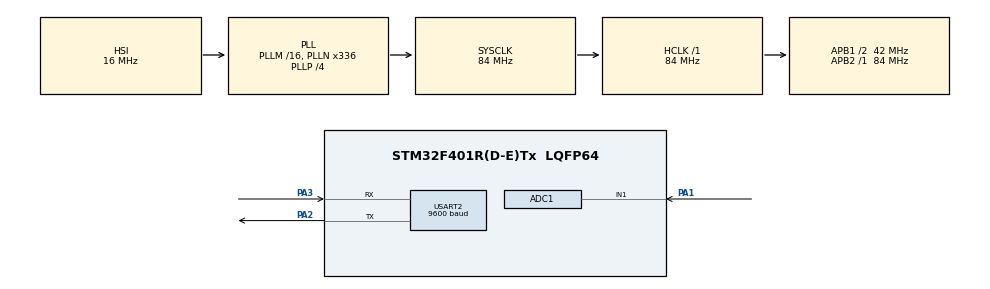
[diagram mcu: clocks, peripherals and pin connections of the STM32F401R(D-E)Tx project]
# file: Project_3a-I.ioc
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ADC1.Channel-0\#ChannelRegularConversion=ADC_CHANNEL_1
ADC1.NbrOfConversion=1
ADC1.NbrOfConversionFlag=1
ADC1.Rank-0\#ChannelRegularConversion=1
ADC1.SamplingTime-0\#ChannelRegularConversion=ADC_SAMPLETIME_480CYCLES
ADC1.master=1
Mcu.Family=STM32F4
Mcu.Name=STM32F401R(D-E)Tx
Mcu.Package=LQFP64
NVIC.PriorityGroup=NVIC_PRIORITYGROUP_0
PA1.Signal=ADCx_IN1
PA13.GPIO_Label=TMS
PA13.Mode=Serial_Wire
PA13.Signal=SYS_JTMS-SWDIO
PA14.GPIO_Label=TCK
PA14.Mode=Serial_Wire
PA14.Signal=SYS_JTCK-SWCLK
PA2.Mode=Asynchronous
PA2.Signal=USART2_TX
PA3.Mode=Asynchronous
PA3.Signal=USART2_RX
PB3.GPIO_Label=SWO
PB3.Signal=SYS_JTDO-SWO
ProjectManager.HeapSize=0x200
ProjectManager.StackSize=0x400
ProjectManager.TargetToolchain=MDK-ARM V5
RCC.48MHZClocksFreq_Value=48000000
RCC.AHBFreq_Value=84000000
RCC.APB1CLKDivider=RCC_HCLK_DIV2
RCC.APB1Freq_Value=42000000
RCC.APB1TimFreq_Value=84000000
RCC.APB2Freq_Value=84000000
RCC.APB2TimFreq_Value=84000000
RCC.CortexFreq_Value=84000000
RCC.HCLKFreq_Value=84000000
RCC.HSE_VALUE=8000000
RCC.HSI_VALUE=16000000
RCC.LSE_VALUE=32768
RCC.PLLN=336
RCC.PLLP=RCC_PLLP_DIV4
RCC.PLLQ=7
RCC.SYSCLKFreq_VALUE=84000000
RCC.SYSCLKSource=RCC_SYSCLKSOURCE_PLLCLK
RCC.VCOOutputFreq_Value=336000000
SH.ADCx_IN1.0=ADC1_IN1,IN1
USART2.BaudRate=9600
USART2.VirtualMode=VM_ASYNC
board=NUCLEO-F401RE

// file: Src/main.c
/* USER CODE BEGIN Header */
/**
  ******************************************************************************
  * @file           : main.c
  * @brief          : Main program body
  ******************************************************************************
  * @attention
  *
  * <h2><center>&copy; Copyright (c) 2019 STMicroelectronics.
  * All rights reserved.</center></h2>
  *
  * This software component is licensed by ST under BSD 3-Clause license,
  * the "License"; You may not use this file except in compliance with the
  * License. You may obtain a copy of the License at:
  *                        opensource.org/licenses/BSD-3-Clause
  *
  ******************************************************************************
  */
/* USER CODE END Header */

#include "main.h"

/* USER CODE BEGIN Includes */
#include "stdio.h"
#include "string.h"
/* USER CODE END Includes */

ADC_HandleTypeDef hadc1;

UART_HandleTypeDef huart2;

/* USER CODE BEGIN PV */
int value = 0;							// 12 bit value from the ADC
float conv;									// value converted to voltage
char newline[2] = "\r\n";		// define standard terminator for string
char string[10];						// value converted to string for transmission
/* USER CODE END PV */

void SystemClock_Config(void);
static void MX_GPIO_Init(void);
static void MX_USART2_UART_Init(void);
static void MX_ADC1_Init(void);

int main(void)
{

  /* MCU Configuration--------------------------------------------------------*/

  /* Reset of all peripherals, Initializes the Flash interface and the Systick. */
  HAL_Init();

  /* Configure the system clock */
  SystemClock_Config();

  /* Initialize all configured peripherals */
  MX_GPIO_Init();
  MX_USART2_UART_Init();
  MX_ADC1_Init();
  /* USER CODE BEGIN 2 */
	HAL_ADC_Start(&hadc1); 			// start single conversion
  /* USER CODE END 2 */

  /* Infinite loop */
  /* USER CODE BEGIN WHILE */
  while (1)
  {
		HAL_ADC_Start(&hadc1);		// start single conversion
		// check if a value has been sampled
		if(HAL_ADC_PollForConversion(&hadc1, HAL_MAX_DELAY) == HAL_OK)
		{
			value = HAL_ADC_GetValue(&hadc1);
			conv = value/4095.000*3.30;
		}
		// stop ADC (doesn't seem necessary as we are in single conversion mode)
		//HAL_ADC_Stop(&hadc1);
		// USART send
		sprintf(string, "%.2f", conv);
		HAL_UART_Transmit(&huart2, (uint8_t *) string, strlen(string), 10);
		HAL_UART_Transmit(&huart2, (uint8_t *) newline, strlen(newline), 10);
		HAL_Delay(1000);
    /* USER CODE END WHILE */

  }
}

void SystemClock_Config(void)
{
  RCC_OscInitTypeDef RCC_OscInitStruct = {0};
  RCC_ClkInitTypeDef RCC_ClkInitStruct = {0};

  /** Configure the main internal regulator output voltage
  */
  __HAL_RCC_PWR_CLK_ENABLE();
  __HAL_PWR_VOLTAGESCALING_CONFIG(PWR_REGULATOR_VOLTAGE_SCALE2);
  /** Initializes the CPU, AHB and APB busses clocks
  */
  RCC_OscInitStruct.OscillatorType = RCC_OSCILLATORTYPE_HSI;
  RCC_OscInitStruct.HSIState = RCC_HSI_ON;
  RCC_OscInitStruct.HSICalibrationValue = RCC_HSICALIBRATION_DEFAULT;
  RCC_OscInitStruct.PLL.PLLState = RCC_PLL_ON;
  RCC_OscInitStruct.PLL.PLLSource = RCC_PLLSOURCE_HSI;
  RCC_OscInitStruct.PLL.PLLM = 16;
  RCC_OscInitStruct.PLL.PLLN = 336;
  RCC_OscInitStruct.PLL.PLLP = RCC_PLLP_DIV4;
  RCC_OscInitStruct.PLL.PLLQ = 7;
  if (HAL_RCC_OscConfig(&RCC_OscInitStruct) != HAL_OK)
  {
    Error_Handler();
  }
  /** Initializes the CPU, AHB and APB busses clocks
  */
  RCC_ClkInitStruct.ClockType = RCC_CLOCKTYPE_HCLK|RCC_CLOCKTYPE_SYSCLK
                              |RCC_CLOCKTYPE_PCLK1|RCC_CLOCKTYPE_PCLK2;
  RCC_ClkInitStruct.SYSCLKSource = RCC_SYSCLKSOURCE_PLLCLK;
  RCC_ClkInitStruct.AHBCLKDivider = RCC_SYSCLK_DIV1;
  RCC_ClkInitStruct.APB1CLKDivider = RCC_HCLK_DIV2;
  RCC_ClkInitStruct.APB2CLKDivider = RCC_HCLK_DIV1;

  if (HAL_RCC_ClockConfig(&RCC_ClkInitStruct, FLASH_LATENCY_2) != HAL_OK)
  {
    Error_Handler();
  }
}

static void MX_ADC1_Init(void)
{

  ADC_ChannelConfTypeDef sConfig = {0};

  /** Configure the global features of the ADC (Clock, Resolution, Data Alignment and number of conversion)
  */
  hadc1.Instance = ADC1;
  hadc1.Init.ClockPrescaler = ADC_CLOCK_SYNC_PCLK_DIV4;
  hadc1.Init.Resolution = ADC_RESOLUTION_12B;
  hadc1.Init.ScanConvMode = DISABLE;
  hadc1.Init.ContinuousConvMode = DISABLE;
  hadc1.Init.DiscontinuousConvMode = DISABLE;
  hadc1.Init.ExternalTrigConvEdge = ADC_EXTERNALTRIGCONVEDGE_NONE;
  hadc1.Init.ExternalTrigConv = ADC_SOFTWARE_START;
  hadc1.Init.DataAlign = ADC_DATAALIGN_RIGHT;
  hadc1.Init.NbrOfConversion = 1;
  hadc1.Init.DMAContinuousRequests = DISABLE;
  hadc1.Init.EOCSelection = ADC_EOC_SINGLE_CONV;
  if (HAL_ADC_Init(&hadc1) != HAL_OK)
  {
    Error_Handler();
  }
  /** Configure for the selected ADC regular channel its corresponding rank in the sequencer and its sample time.
  */
  sConfig.Channel = ADC_CHANNEL_1;
  sConfig.Rank = 1;
  sConfig.SamplingTime = ADC_SAMPLETIME_480CYCLES;
  if (HAL_ADC_ConfigChannel(&hadc1, &sConfig) != HAL_OK)
  {
    Error_Handler();
  }

}

static void MX_USART2_UART_Init(void)
{

  huart2.Instance = USART2;
  huart2.Init.BaudRate = 9600;
  huart2.Init.WordLength = UART_WORDLENGTH_8B;
  huart2.Init.StopBits = UART_STOPBITS_1;
  huart2.Init.Parity = UART_PARITY_NONE;
  huart2.Init.Mode = UART_MODE_TX_RX;
  huart2.Init.HwFlowCtl = UART_HWCONTROL_NONE;
  huart2.Init.OverSampling = UART_OVERSAMPLING_16;
  if (HAL_UART_Init(&huart2) != HAL_OK)
  {
    Error_Handler();
  }

}

static void MX_GPIO_Init(void)
{

  /* GPIO Ports Clock Enable */
  __HAL_RCC_GPIOA_CLK_ENABLE();
  __HAL_RCC_GPIOB_CLK_ENABLE();

}

void Error_Handler(void)
{
}

/************************ (C) COPYRIGHT STMicroelectronics *****END OF FILE****/
